# ATmega169PA register map
Vendor: Atmel; File version: 1.0
CPU: other r0p0, little endian, no MPU, no FPU, 4 interrupt priority bits
Registers are 8-bit, read-write, reset 0x0 unless marked. A register's access mark holds for its fields unless they carry their own. Offsets are from the block's base; [hi:lo] are bit positions.

## TC1 — Timer/Counter, 16-bit
Base 0x00000036
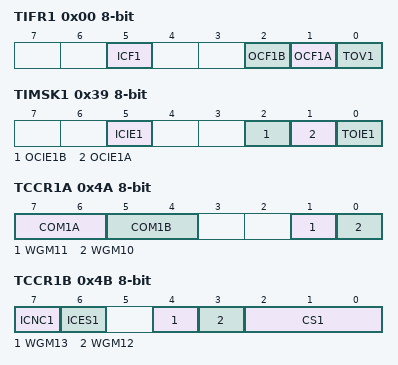
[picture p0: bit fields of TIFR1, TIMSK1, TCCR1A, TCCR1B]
0x00 TIFR1 — Timer/Counter1 Interrupt Flag register
  [5] ICF1 — Input Capture Flag 1
  [2] OCF1B — Output Compare Flag 1B
  [1] OCF1A — Output Compare Flag 1A
  [0] TOV1 — Timer/Counter1 Overflow Flag
0x39 TIMSK1 — Timer/Counter1 Interrupt Mask Register
  [5] ICIE1 — Timer/Counter1 Input Capture Interrupt Enable
  [2] OCIE1B — Timer/Counter1 Output Compare B Match Interrupt Enable
  [1] OCIE1A — Timer/Counter1 Output Compare A Match Interrupt Enable
  [0] TOIE1 — Timer/Counter1 Overflow Interrupt Enable
0x4A TCCR1A — Timer/Counter1 Control Register A
  [7:6] COM1A — Compare Output Mode 1A, bits
  [5:4] COM1B — Compare Output Mode 1B, bits
  [1] WGM11 — Waveform Generation Mode
  [0] WGM10 — Waveform Generation Mode
0x4B TCCR1B — Timer/Counter1 Control Register B
  [7] ICNC1 — Input Capture 1 Noise Canceler
  [6] ICES1 — Input Capture 1 Edge Select
  [4] WGM13 — Waveform Generation Mode
  [3] WGM12 — Waveform Generation Mode
  [2:0] CS1 — Prescaler source of Timer/Counter 1
    0=No Clock Source (Stopped); 1=Running, No Prescaling; 2=Running, CLK/8; 3=Running, CLK/64; 4=Running, CLK/256; 5=Running, CLK/1024; 6=Running, ExtClk Tx Falling Edge; 7=Running, ExtClk Tx Rising Edge
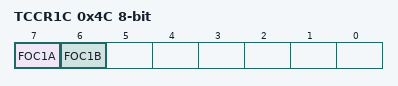
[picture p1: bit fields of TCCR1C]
0x4C TCCR1C — Timer/Counter 1 Control Register C
  [7] FOC1A — Force Output Compare 1A
  [6] FOC1B — Force Output Compare 1B
0x4E TCNT1 16-bit (reset mask 0xFF) — Timer/Counter1 Bytes
  [15:0] TCNT1 — Timer/Counter1 bits
0x50 ICR1 16-bit (reset mask 0xFF) — Timer/Counter1 Input Capture Register Bytes
  [15:0] ICR1 — Timer/Counter1 Input Capture
0x52 OCR1A 16-bit (reset mask 0xFF) — Timer/Counter1 Output Compare Register A Bytes
  [15:0] OCR1A — Timer/Counter1 Output Compare A
0x54 OCR1B 16-bit (reset mask 0xFF) — Timer/Counter1 Output Compare Register B Bytes
  [15:0] OCR1B — Timer/Counter1 Output Compare B

## TC2 — Timer/Counter, 8-bit Async
Base 0x00000037
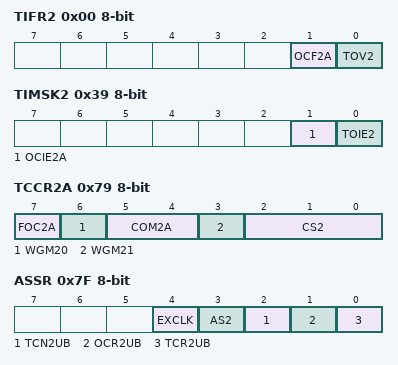
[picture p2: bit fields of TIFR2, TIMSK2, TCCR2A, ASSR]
0x00 TIFR2 — Timer/Counter2 Interrupt Flag Register
  [1] OCF2A — Timer/Counter2 Output Compare Flag 2
  [0] TOV2 — Timer/Counter2 Overflow Flag
0x0C GTCCR — General Timer/Counter Control Register
  [1] PSR2 — Prescaler Reset Timer/Counter2
0x39 TIMSK2 — Timer/Counter2 Interrupt Mask register
  [1] OCIE2A — Timer/Counter2 Output Compare Match Interrupt Enable
  [0] TOIE2 — Timer/Counter2 Overflow Interrupt Enable
0x79 TCCR2A — Timer/Counter2 Control Register
  [7] FOC2A — Force Output Compare A
  [6] WGM20 — Waveform Generation Mode
    0=Normal; 1=CTC
  [5:4] COM2A — Compare Output Mode bits
  [3] WGM21 — Waveform Generation Mode
  [2:0] CS2 — Clock Select bits
    0=No Clock Source (Stopped); 1=Running, No Prescaling; 2=Running, CLK/8; 3=Running, CLK/32; 4=Running, CLK/64; 5=Running, CLK/128; 6=Running, CLK/256; 7=Running, CLK/1024
0x7B TCNT2 — Timer/Counter2
  [7:0] TCNT2 — Timer/Counter2 bits
0x7C OCR2A — Timer/Counter2 Output Compare Register
  [7:0] OCR2A — Timer/Counter2 Output Compare A
0x7F ASSR — Asynchronous Status Register
  [4] EXCLK — Enable External Clock Interrupt
  [3] AS2 — AS2: Asynchronous Timer/Counter2
  [2] TCN2UB — TCN2UB: Timer/Counter2 Update Busy
  [1] OCR2UB — Output Compare Register2 Update Busy
  [0] TCR2UB — TCR2UB: Timer/Counter Control Register2 Update Busy

## USART0 — USART
Base 0x000000C0
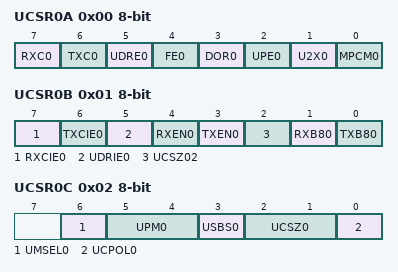
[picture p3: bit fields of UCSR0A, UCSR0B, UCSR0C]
0x00 UCSR0A — USART Control and Status Register A
  [7] RXC0 — USART Receive Complete
  [6] TXC0 — USART Transmit Complete
  [5] UDRE0 — USART Data Register Empty
  [4] FE0 — Framing Error
  [3] DOR0 — Data OverRun
  [2] UPE0 — USART Parity Error
  [1] U2X0 — Double the USART Transmission Speed
  [0] MPCM0 — Multi-processor Communication Mode
0x01 UCSR0B — USART Control and Status Register B
  [7] RXCIE0 — RX Complete Interrupt Enable
  [6] TXCIE0 — TX Complete Interrupt Enable
  [5] UDRIE0 — USART Data Register Empty Interrupt Enable
  [4] RXEN0 — Receiver Enable
  [3] TXEN0 — Transmitter Enable
  [2] UCSZ02 — Character Size
  [1] RXB80 — Receive Data Bit 8
  [0] TXB80 — Transmit Data Bit 8
0x02 UCSR0C — USART Control and Status Register C
  [6] UMSEL0 — USART Mode Select
    0=Asynchronous Operation; 1=Synchronous Operation
  [5:4] UPM0 — Parity Mode Bits
    0=Disabled; 2=Enabled, Even Parity; 3=Enabled, Odd Parity
  [3] USBS0 — Stop Bit Select
    0=1-bit; 1=2-bit
  [2:1] UCSZ0 — Character Size
  [0] UCPOL0 — Clock Polarity
0x04 UBRR0 16-bit (reset mask 0xFF) — USART Baud Rate Register Bytes
  [11:0] UBRR0 — USART Baud Rate bits
0x06 UDR0 — USART I/O Data Register
  [7:0] UDR0 — USART I/O Data bits

## USI — Universal Serial Interface
Base 0x000000B8
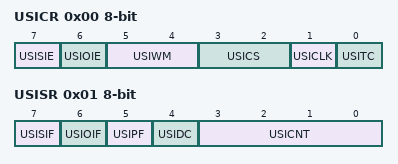
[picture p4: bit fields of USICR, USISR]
0x00 USICR — USI Control Register
  [7] USISIE — Start Condition Interrupt Enable
  [6] USIOIE — Counter Overflow Interrupt Enable
  [5:4] USIWM — USI Wire Mode Bits
    0=Normal Operation; 1=Three-Wire Mode; 2=Two-Wire Mode; 3=Two-Wire Mode Held Low
  [3:2] USICS — USI Clock Source Select Bits
  [1] USICLK — Clock Strobe
  [0] USITC — Toggle Clock Port Pin
0x01 USISR — USI Status Register
  [7] USISIF — Start Condition Interrupt Flag
  [6] USIOIF — Counter Overflow Interrupt Flag
  [5] USIPF — Stop Condition Flag
  [4] USIDC — Data Output Collision
  [3:0] USICNT — USI Counter Value Bits
0x02 USIDR — USI Data Register
  [7:0] USIDR — USI Data bits

## WDT — Watchdog Timer
Base 0x00000060
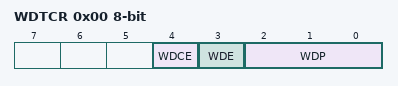
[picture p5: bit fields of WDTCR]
0x00 WDTCR — Watchdog Timer Control Register
  [4] WDCE — Watchdog Change Enable
  [3] WDE — Watch Dog Enable
  [2:0] WDP — Watch Dog Timer Prescaler bits
    0=Oscillator Cycles 16K; 1=Oscillator Cycles 32K; 2=Oscillator Cycles 64K; 3=Oscillator Cycles 128K; 4=Oscillator Cycles 256K; 5=Oscillator Cycles 512K; 6=Oscillator Cycles 1024K; 7=Oscillator Cycles 2048K
